# girlsoc register map
Vendor: luna-soc
TODO device.description
Registers are 8-bit, read-write, reset 0x0 unless marked. A register's access mark holds for its fields unless they carry their own. Offsets are from the block's base; lines under a group give offsets from that group; [hi:lo] are bit positions; {n}, {i} and the like mark numbered series; 'fields as' and 'values as' point back to an identical list; <NAME> marks a mode.

## Memory map
0xA0000000 I2CFIFO size 0x100
0xF0000100 spiflash_ctrl size 0xC
0xF0000200 uart0 size 0x14
0xF0000300 timer0 size 0x12
0xF0000500 led0 size 0x4
0xF0000600 gpo1 size 0x4
0xF0000700 gpi0 size 0x1

## Interrupts
0 timer0

## gpi0
Base 0xF0000700
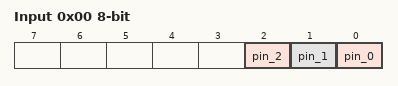
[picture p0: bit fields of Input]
0x00 Input — A CSR register. Parameters ---------- fields : :class:`dict` or :class:`list` or :class:`Field` Collection of register fields. If ``None`` (default), a dict is populated from Python :term:`variable annotations <python:variable annotations>`. ``fields`` is used to create a :class:`FieldActionMap`, :class:`FieldActionArray`, or :class:`FieldAction`, depending on its type (dict, list, or Field). Interface attributes -------------------- element : :class:`Element` Interface between this register and a CSR bus primitive. Attributes ---------- field : :class:`FieldActionMap` or :class:`FieldActionArray` or :class:`FieldAction` Collection of field instances. f : :class:`FieldActionMap` or :class:`FieldActionArray` or :class:`FieldAction` Shorthand for :attr:`Register.field`. Raises ------ :exc:`TypeError` If ``fields`` is neither ``None``, a :class:`dict`, a :class:`list`, or a :class:`Field`. :exc:`ValueError` If ``fields`` is not ``None`` and at least one variable annotation is a :class:`Field`. :exc:`ValueError` If ``element.access`` is not readable and at least one field is readable. :exc:`ValueError` If ``element.access`` is not writable and at least one field is writable.
  [2] pin_2 ro, [1] pin_1 ro, [0] pin_0 ro

## I2CFIFO
Base 0xA0000000
0x02 I2CC1 reset 0x9A
  [7] i2c_en
0x12 I2CTXFIFO_LSB
  [7:0] txlsb
0x13 I2CTXFIFO_MSB
  [1:0] cmd
0x14 I2CRXFIFO 16-bit
  [7:0] rx_data, [0] dfirst
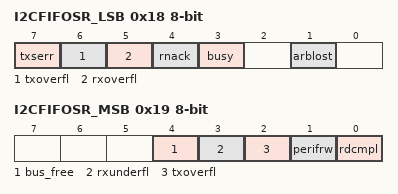
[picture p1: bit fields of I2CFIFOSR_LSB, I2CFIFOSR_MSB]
0x18 I2CFIFOSR_LSB
  [7] txserr, [6] txoverfl, [5] rxoverfl, [4] rnack, [3] busy, [1] arblost
0x19 I2CFIFOSR_MSB
  [4] bus_free, [3] rxunderfl, [2] txoverfl, [1] perifrw, [0] rdcmpl
0x27 I2CTXFIFOBYTEAVAIL
  [0] dfirst
